# K32W041AM register map
Vendor: nxp.com; File version: 1.0
CPU: CM4 r0p1, little endian, MPU, no FPU, VTOR, 3 interrupt priority bits
Registers are 32-bit, read-write, reset 0x0 unless marked. A register's access mark holds for its fields unless they carry their own. Offsets are from the block's base; [hi:lo] are bit positions; {n}, {i} and the like mark numbered series; 'fields as' and 'values as' point back to an identical list.

## ADC0 — This is the description of component adc It is General Purpose ADC. More details will follow.
Base 0x40089000
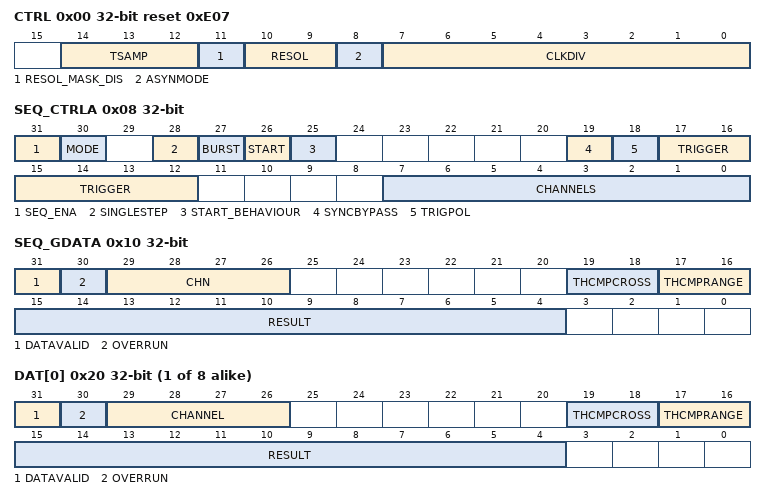
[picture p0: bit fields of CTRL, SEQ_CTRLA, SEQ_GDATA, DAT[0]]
0x00 CTRL reset 0xE07 — ADC Control register. Contains the clock divide value, resolution selection, sampling time selection, and mode controls.
  [14:12] TSAMP — Sample Time. The default sampling period (TSAMP = 000 ) at the start of each conversion is 2.5 ADC clock periods. Depending on a variety of factors, including operating conditions and the output impedance of the analog source, longer sampling times may be required. The TSAMP field should stay to default during application The TSAMP field specifies the number of additional ADC clock cycles, from zero to seven, by which the sample period will be extended. The total conversion time will increase by the same number of clocks. 000 - The sample period will be the default 2.5 ADC clocks. A complete conversion with 12-bits of accuracy will require 15 clocks. 001- The sample period will be extended by one ADC clock to a total of 3.5 clock periods. A complete 12-bit conversion will require 16 clocks. 010 - The sample period will be extended by two clocks to 4.5 ADC clock cycles. A complete 12-bit conversion will require 17 ADC clocks. ... 111 - The sample period will be extended by seven clocks to 9.5 ADC clock cycles. A complete 12-bit conversion will require 22 ADC clocks.
  [11] RESOL_MASK_DIS — According RESOL bit LSB bits are automatickly masked if RESOL_MASK_DIS = 0. If RESOL_MASK_DIS = 1, the 12bits comming from ADC are directly connect to register RESULT
  [10:9] RESOL — The number of bits of ADC resolution. Note, whatever the resolution setting, the ADC data will always be shifted to use the MSBs of any ADC data words. Accuracy can be reduced to achieve higher conversion rates. A single conversion (including one conversion in a burst or sequence) requires the selected number of bits of resolution plus 3 ADC clocks. Remark: This field must only be altered when the ADC is fully idle. Changing it during any kind of ADC operation may have unpredictable results. Remark: ADC clock frequencies for various resolutions must not exceed: - 5x the system clock rate for 12-bit resolution. - 4.3x the system clock rate for 10-bit resolution. - 3.6x the system clock for 8-bit resolution. - 3x the bus clock rate for 6-bit resolution. Settings: 0x3: 6-bit resolution. An ADC conversion requires 9 ADC clocks, plus any clocks specified by the TSAMP field; 0x2: 8-bit resolution. An ADC conversion requires 11 ADC clocks, plus any clocks specified by the TSAMP field; 0x1:10-bit resolution. An ADC conversion requires 13 ADC clocks, plus any clocks specified by the TSAMP field; 0x0: 12-bit resolution. An ADC conversion requires 15 ADC clocks, plus any clocks specified by the TSAMP field.
  [8] ASYNMODE — Select clock mode. 0: Synchronous mode. Not Supported. 1: Asynchronous mode. The ADC clock is based on the output of the ADC clock divider ADCCLKSEL in the SYSCON block.
  [7:0] CLKDIV — Reserved. No changes to this fiedl are necessary.
0x08 SEQ_CTRLA (reset mask 0xDA0FF0FF) — ADC Conversion Sequence-A control register: Controls triggering and channel selection for conversion sequence-A. Also specifies interrupt mode for sequence-A.
  [31] SEQ_ENA — Sequence Enable. In order to avoid spuriously triggering the sequence, care should be taken to only set the SEQA_ENA bit when the selected trigger input is in its INACTIVE state (as defined by the TRIGPOL bit). If this condition is not met, the sequence will be triggered immediately upon being enabled. Remark: In order to avoid spuriously triggering the sequence, care should be taken to only set the SEQA_ENA bit when the selected trigger input is in its INACTIVE state (as defined by the TRIGPOL bit). If this condition is not met, the sequence will be triggered immediately upon being enabled. 0: Disabled. Sequence A is disabled. Sequence A triggers are ignored. If this bit is cleared while sequence A is in progress, the sequence will be halted at the end of the current conversion. After the sequence is re-enabled, a new trigger will be required to restart the sequence beginning with the next enabled channel. 1: Enabled. Sequence A is enabled.
  [30] MODE — Indicates whether the primary method for retrieving conversion results for this sequence will be accomplished via reading the global data register (SEQA_GDAT) at the end of each conversion, or the individual channel result registers at the end of the entire sequence. Impacts when conversion-complete interrupt/DMA trigger for sequence-A will be generated and which overrun conditions contribute to an overrun interrupt as described below. 0: End of conversion. The sequence A interrupt/DMA trigger will be set at the end of each individual ADC conversion performed under sequence A. This flag will mirror the DATAVALID bit in the SEQA_GDAT register. The OVERRUN bit in the SEQA_GDAT register will contribute to generation of an overrun interrupt/DMA trigger if enabled. 1: End of sequence. The sequence A interrupt/DMA trigger will be set when the entire set of sequence-A conversions completes. This flag will need to be explicitly cleared by software or by the DMA-clear signal in this mode. The OVERRUN bit in the SEQA_GDAT register will NOT contribute to generation of an overrun interrupt/DMA trigger since it is assumed this register may not be utilized in this mode.
  [28] SINGLESTEP — When this bit is set, a hardware trigger or a write to the START bit will launch a single conversion on the next channel in the sequence instead of the default response of launching an entire sequence of conversions. Once all of the channels comprising a sequence have been converted, a subsequent trigger will repeat the sequence beginning with the first enabled channel. Interrupt generation will still occur either after each individual conversion or at the end of the entire sequence, depending on the state of the MODE bit.
  [27] BURST — Writing a 1 to this bit will cause this conversion sequence to be continuously cycled through. Other sequence A triggers will be ignored while this bit is set. Repeated conversions can be halted by clearing this bit. The sequence currently in progress will be completed before conversions are terminated. Note that a new sequence could begin just before BURST is cleared.
  [26] START wo — Writing a 1 to this field will launch one pass through this conversion sequence. The behavior will be identical to a sequence triggered by a hardware trigger. Do not write 1 to this bit if the BURST bit is set. Remark: This bit is only set to a 1 momentarily when written to launch a conversion sequence. It will consequently always read back as a zero.
  [25] START_BEHAVIOUR — the Start behavior used on gpadc: writing 0 for repeat start after each input selection changed, used for seqA with multiple inputs. writing 1 for continuous start, this bit is only if seqA is used to have full speed on a single input. Remark: with 0 the word rate is divided by two.
  [19] SYNCBYPASS — Setting this bit allows the hardware trigger input to bypass synchronization flip-flop stages and therefore shorten the time between the trigger input signal and the start of a conversion. There are slightly different criteria for whether or not this bit can be set depending on the clock operating mode: Synchronous mode (the ASYNMODE in the CTRL register = 0): Synchronization may be bypassed (this bit may be set) if the selected trigger source is already synchronous with the main system clock (eg. coming from an on-chip, system-clock-based timer). Whether this bit is set or not, a trigger pulse must be maintained for at least one system clock period. Asynchronous mode (the ASYNMODE in the CTRL register = 1): Synchronization may be bypassed (this bit may be set) if it is certain that the duration of a trigger input pulse will be at least one cycle of the ADC clock (regardless of whether the trigger comes from and on-chip or off-chip source). If this bit is NOT set, the trigger pulse must at least be maintained for one system clock period. 0: Enable trigger synchronization. The hardware trigger bypass is not enabled. 1: Bypass trigger synchronization. The hardware trigger bypass is enabled.
  [18] TRIGPOL — Select the polarity of the selected input trigger for this conversion sequence. Remark: In order to avoid generating a spurious trigger, it is recommended writing to this field only when SEQA_ENA (bit 31) is low. It is safe to change this field and set bit 31 in the same write. 0: A negative edge launches the conversion sequence on the selected trigger input. 1: A positive edge launches the conversion sequence on the selected trigger input.
  [17:12] TRIGGER — Selects which of the available hardware trigger sources will cause this conversion sequence to be initiated. Program the trigger input number in this field. Setting: 0 : PINT0; 1 : PWM8; 2 : PWM9; 3 : ARM TX EV. Remark: In order to avoid generating a spurious trigger, it is recommended writing to+I32 this field only when SEQA_ENA (bit 31) is low. It is safe to change this field and set bit 31 in the same write.
  [7:0] CHANNELS — Selects which one or more of the ADC channels will be sampled and converted when this sequence is launched. A 1 in any bit of this field will cause the corresponding channel to be included in the conversion sequence, where bit 0 corresponds to channel 0, bit 1 to channel 1 and so forth. Bit 6 is channel 6; the supply monitor. Bit 7 is channel 7; the temperature sensor. When this conversion sequence is triggered, either by a hardware trigger or via software command, ADC conversions will be performed on each enabled channel, in sequence, beginning with the lowest-ordered channel. Remark: This field can ONLY be changed while SEQA_ENA (bit 31) is LOW. It is allowed to change this field and set bit 31 in the same write.
0x10 SEQ_GDATA ro — ADC Sequence-A Global Data register. This register contains the result of the most recent ADC conversion performed under sequence-A.
  [31] DATAVALID — This bit is set to 1 at the end of each conversion when a new result is loaded into the RESULT field. It is cleared whenever this register is read. This bit will cause a conversion-complete interrupt for the corresponding sequence if the MODE bit (in SEQA_CTRL) for that sequence is set to 0 (and if the interrupt is enabled).
  [30] OVERRUN — This bit is set if a new conversion result is loaded into the RESULT field before a previous result has been read - i.e. while the DATAVALID bit is set. This bit is cleared, along with the DATAVALID bit, whenever this register is read. This bit will contribute to an overrun interrupt/DMA trigger if the MODE bit (in SEQA_CTRL) for the corresponding sequence is set to 0 (and if the overrun interrupt is enabled).
  [29:26] CHN — These bits contain the channel from which the RESULT bits were converted (e.g. 0000 identifies channel 0, 0001 channel 1, etc.).
  [19:18] THCMPCROSS — Threshold Crossing Comparison result. 0x0 = No threshold Crossing detected: The most recent completed conversion on this channel had the same relationship (above or below) to the threshold value established by the designated LOW threshold register (THRn_LOW) as did the previous conversion on this channel. 0x1 = Reserved. 0x2 = Downward Threshold Crossing Detected. Indicates that a threshold crossing in the downward direction has occurred - i.e. the previous sample on this channel was above the threshold value established by the designated LOW threshold register (THRn_LOW) and the current sample is below that threshold. 0x3 = Upward Threshold Crossing Detected. Indicates that a threshold crossing in the upward direction has occurred - i.e. the previous sample on this channel was below the threshold value established by the designated LOW threshold register (THRn_LOW) and the current sample is above that threshold.
  [17:16] THCMPRANGE — Threshold Range Comparison result. 0x0 = In Range: The last completed conversion was greater than or equal to the value programmed into the designated LOW threshold register (THRn_LOW) but less than or equal to the value programmed into the designated HIGH threshold register (THRn_HIGH). 0x1 = Below Range: The last completed conversion on was less than the value programmed into the designated LOW threshold register (THRn_LOW). 0x2 = Above Range: The last completed conversion was greater than the value programmed into the designated HIGH threshold register (THRn_HIGH). 0x3 = Reserved.
  [15:4] RESULT — This field contains the 12-bit ADC conversion result from the most recent conversion performed under conversion sequence associated with this register. DATAVALID = 1 indicates that this result has not yet been read. If less than 12-bit resolultion is used the ADC result occupies the upper MSBs and unused LSBs should be ignored.
{0x20+4i} DAT[{i}] (i=0..7) ro — ADC Channel X [0:7] Data register. This register contains the result of the most recent conversion completed on channel X [0:7] .
  [31] DATAVALID — This bit is set to 1 at the end of each conversion for this channel when a new result is loaded into the RESULT field. It is cleared whenever this register is read or when the data related to this channel is read from the global SEQA_GDAT regsiter.
  [30] OVERRUN — This bit is set if a new conversion result is loaded into the RESULT field before a previous result has been read - i.e. while the DATAVALID bit is set. This bit is cleared, along with the DATAVALID bit, whenever this register is read or when the data related to this channel is read from the global SEQA_GDAT register. This bit will contribute to an overrun interrupt/DMA trigger if the MODE bit (in SEQA_CTRL) for the corresponding sequence is set to 0 (and if the overrun interrupt is enabled).
  [29:26] CHANNEL — This field is hard-coded to contain the channel number that this particular register relates to (i.e. this field will contain 0b0000 for the DAT0 register, 0b0001 for the DAT1 register, etc)
  [19:18] THCMPCROSS — Threshold Crossing Comparison result for this channel. 0x0 = No threshold Crossing detected: The most recent completed conversion on this channel had the same relationship (above or below) to the threshold value established by the designated LOW threshold register (THRn_LOW) as did the previous conversion on this channel. 0x1 = Reserved. 0x2 = Downward Threshold Crossing Detected. Indicates that a threshold crossing in the downward direction has occurred - i.e. the previous sample on this channel was above the threshold value established by the designated LOW threshold register (THRn_LOW) and the current sample is below that threshold. 0x3 = Upward Threshold Crossing Detected. Indicates that a threshold crossing in the upward direction has occurred - i.e. the previous sample on this channel was below the threshold value established by the designated LOW threshold register (THRn_LOW) and the current sample is above that threshold.
  [17:16] THCMPRANGE — Threshold Range Comparison result for this channel. 0x0 = In Range: The last completed conversion was greater than or equal to the value programmed into the designated LOW threshold register (THRn_LOW) but less than or equal to the value programmed into the designated HIGH threshold register (THRn_HIGH). 0x1 = Below Range: The last completed conversion on was less than the value programmed into the designated LOW threshold register (THRn_LOW). 0x2 = Above Range: The last completed conversion was greater than the value programmed into the designated HIGH threshold register (THRn_HIGH). 0x3 = Reserved.
  [15:4] RESULT — This field contains the 12-bit ADC conversion result from the most recent conversion performed for this channel under conversion sequence associated with this register. DATAVALID = 1 indicates that this result has not yet been read. If less than 12-bit resolultion is used the ADC result occupies the upper MSBs and unused LSBs should be ignored.
0x50 THR0_LOW — ADC Low Compare Threshold register 0: Contains the lower threshold level for automatic threshold comparison for any channels linked to threshold pair 0.
  [15:4] THRLOW — Low threshold value against which ADC results will be compared
0x54 THR1_LOW — ADC Low Compare Threshold register 1: Contains the lower threshold level for automatic threshold comparison for any channels linked to threshold pair 1.
  fields as THR0_LOW
0x58 THR0_HIGH — ADC High Compare Threshold register 0: Contains the upper threshold level for automatic threshold comparison for any channels linked to threshold pair 0.
  [15:4] THRHIGH — High threshold value against which ADC results will be compared
0x5C THR1_HIGH — ADC High Compare Threshold register 1: Contains the upper threshold level for automatic threshold comparison for any channels linked to threshold pair 1.
  fields as THR0_HIGH
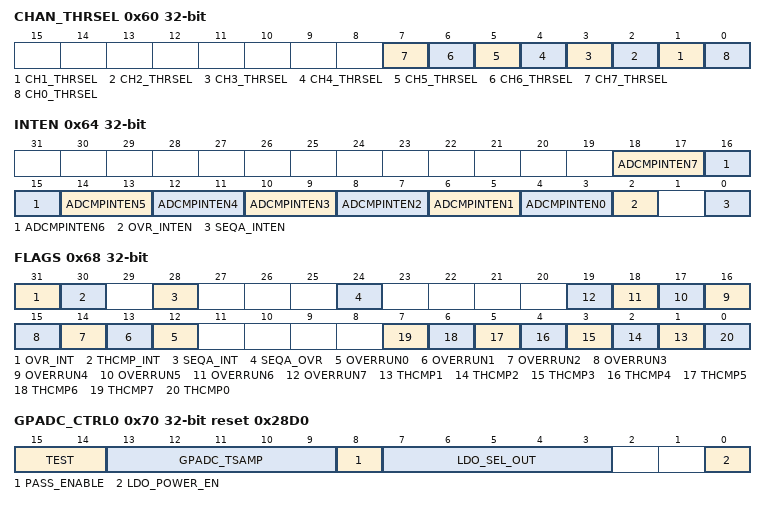
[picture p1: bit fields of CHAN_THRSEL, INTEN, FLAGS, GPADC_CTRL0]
0x60 CHAN_THRSEL — ADC Channel-Threshold Select register. Specifies which set of threshold compare registers are to be used for each channel
  [n] CH{n}_THRSEL (n=1..7) — Threshold select for channel {n}. See description for channel 0.
  [0] CH0_THRSEL — Threshold select for channel 0. 0: Threshold 0. Results for this channel will be compared against the threshold levels indicated in the THR0_LOW and THR0_HIGH registers. 1: Threshold 1. Results for this channel will be compared against the threshold levels indicated in the THR1_LOW and THR1_HIGH registers.
0x64 INTEN — ADC Interrupt Enable register. This register contains enable bits that enable the sequence-A, sequence-B, threshold compare and data overrun interrupts to be generated.
  [2n+4:2n+3] ADCMPINTEN{n} (n=1..7) — Channel {n} threshold comparison interrupt enable. See description for channel 0.
  [4:3] ADCMPINTEN0 — Threshold comparison interrupt enable for channel 0. 0x0: Disabled. 0x1: Outside threshold. 0x2: Crossing threshold. 0x3: Reserved
  [2] OVR_INTEN — Overrun interrupt enable. 0: Disabled. The overrun interrupt is disabled. 1: Enabled. The overrun interrupt is enabled. Detection of an overrun condition on any of the 12 channel data registers will cause an overrun interrupt/DMA trigger. In addition, if the MODE bit for a particular sequence is 0, then an overrun in the global data register for that sequence will also cause this interrupt/DMA trigger to be asserted.
  [0] SEQA_INTEN — Sequence A interrupt enable. 0: Disabled. The sequence A interrupt/DMA trigger is disabled. 1: Enabled. The sequence A interrupt/DMA trigger is enabled and will be asserted either upon completion of each individual conversion performed as part of sequence A, or upon completion of the entire A sequence of conversions, depending on the MODE bit in the SEQA_CTRL register.
0x68 FLAGS — ADC Flags register. Contains the four interrupt/DMA trigger flags and the individual component overrun and threshold-compare flags. (The overrun bits replicate information stored in the result registers).
  [31] OVR_INT ro — Overrun Interrupt flag. Any overrun bit in any of the individual channel data registers will cause this interrupt. In addition, if the MODE bit in either of the SEQn_CTRL registers is 0 then the OVERRUN bit in the corresponding SEQn_GDAT register will also cause this interrupt. This interrupt must be enabled in the INTEN register. This bit will be cleared when all of the individual overrun bits have been cleared via reading the corresponding data registers.
  [30] THCMP_INT ro — Threshold Comparison Interrupt. This bit will be set if any of the THCMP flags in the lower bits of this register are set to 1 (due to an enabled out-of-range or threshold-crossing event on any channel). Each type of threshold comparison interrupt on each channel must be individually enabled in the INTEN register to cause this interrupt. This bit will be cleared when all of the individual threshold flags are cleared via writing 1s to those bits.
  [28] SEQA_INT — Sequence A interrupt/DMA trigger. If the MODE bit in the SEQA_CTRL register is 0, this flag will mirror the DATAVALID bit in the sequence A global data register (SEQA_GDAT), which is set at the end of every ADC conversion performed as part of sequence A. It will be cleared automatically when the SEQA_GDAT register is read. If the MODE bit in the SEQA_CTRL register is 1, this flag will be set upon completion of an entire A sequence. In this case it must be cleared by writing a 1 to this SEQA_INT bit. This interrupt must be enabled in the INTEN register.
  [24] SEQA_OVR ro — Mirrors the global OVERRUN status flag in the SEQA_GDAT register
  [n+12] OVERRUN{n} ro (n=0..7) — Mirrors the OVERRRUN status flag from the result register for ADC channel {n}
  [n] THCMP{n} (n=1..7) — Threshold comparison event on Channel {n}. See description for channel 0.
  [0] THCMP0 — Threshold comparison event on Channel 0. Set to 1 upon either an out-of-range result or a threshold-crossing result if enabled to do so in the INTEN register. This bit is cleared by writing a 1.
0x6C STARTUP — ADC Startup register (typically only used by the ADC API).
  [0] ADC_ENA — ADC Enable bit. This bit can only be set to a 1 by software. It is cleared automatically whenever the ADC is powered down. This bit must not be set until at least 10 microseconds after the ADC is powered up (typically by altering a system-level ADC power control bit).
0x70 GPADC_CTRL0 reset 0x28D0 — Second ADC Control register : ADC internal LDO (within ADC sub-system)
  [15:14] TEST — Mode selection: '00': Normal functional mode (DIV4 mode). Input range is 0 to 3.6V, although max input voltage is affected by supply voltage of the device. '01': Multiplexer test mode '10': ADC in unity gain mode. (DIV1 mode). Input range is 0 to 0.9V. Voltages above this may damage the device. '11': Not used
  [13:9] GPADC_TSAMP — Extand ADC sampling time according to source impedance 1: 0.621 kOhm 20 (default): 55 kOhm 31: 87 kOhm
  [8] PASS_ENABLE — Enable pass mode when set to high. This is for the LDO within the ADC itself. There is also LDOADC controlled from PMC that is outside the ADC block.
  [7:3] LDO_SEL_OUT — Select LDO output voltage (10mV step) [between 0.64V and 0.95V]. This is for the LDO within the ADC itself. There is also LDOADC controlled from PMC that is outside the ADC block.
  [0] LDO_POWER_EN — LDO Power enable signal (active high). This is for the LDO within the ADC itself. There is also LDOADC controlled from PMC that is outside the ADC block. The LDOADC should have been enabled for 10usec before enabling this LDO. After enabling this LDO it is necessary to wait for 230usec, before ADC sampling is commenced, so that full accuraccy of the ADC will be obtained.
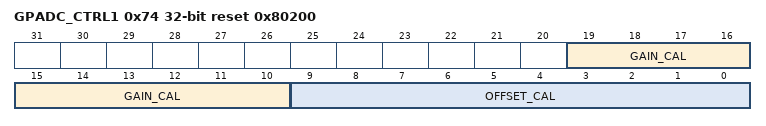
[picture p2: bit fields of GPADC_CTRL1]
0x74 GPADC_CTRL1 reset 0x80200 — Third ADC Control register : ADC internal gain and offset
  [19:10] GAIN_CAL — gain_cal the setting is used within the ADC to compensate for any gain variation for this particular device.
  [9:0] OFFSET_CAL — offset_cal the setting is used within the ADC to compensate for a DC shift in values for this particular device.
